VERSION ""

NS_ :

BS_:

BU_:

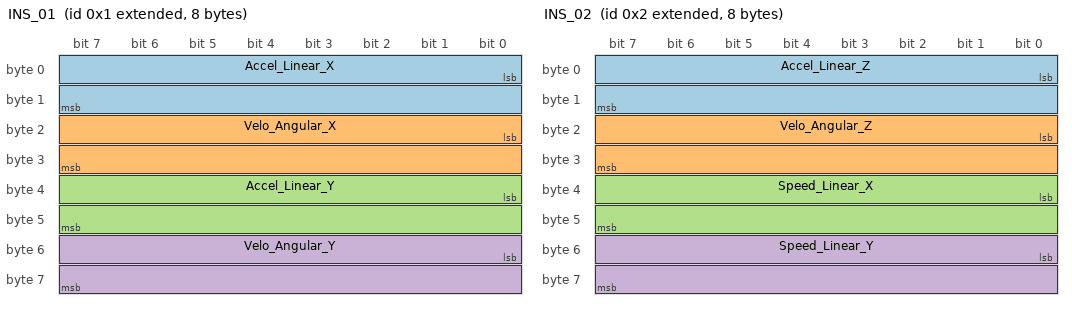
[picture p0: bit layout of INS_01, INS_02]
BO_ 2147483649 INS_01: 8 Vector__XXX
 SG_ Accel_Linear_X : 0|16@1- (0.01,0) [0|0] "" Vector__XXX
 SG_ Velo_Angular_X : 16|16@1- (0.01,0) [0|0] "" Vector__XXX
 SG_ Accel_Linear_Y : 32|16@1- (0.01,0) [0|0] "" Vector__XXX
 SG_ Velo_Angular_Y : 48|16@1- (0.01,0) [0|0] "" Vector__XXX

BO_ 2147483650 INS_02: 8 Vector__XXX
 SG_ Accel_Linear_Z : 0|16@1- (0.01,0) [0|0] "" Vector__XXX
 SG_ Velo_Angular_Z : 16|16@1- (0.01,0) [0|0] "" Vector__XXX
 SG_ Speed_Linear_X : 32|16@1- (0.01,0) [0|0] "" Vector__XXX
 SG_ Speed_Linear_Y : 48|16@1- (0.01,0) [0|0] "" Vector__XXX
